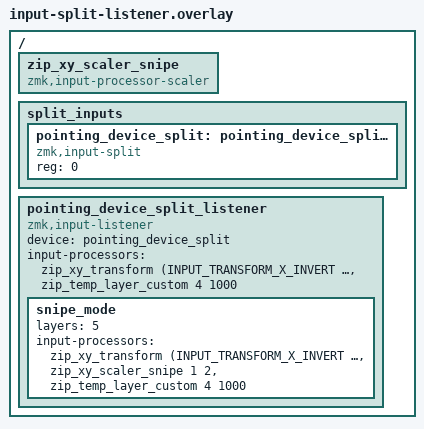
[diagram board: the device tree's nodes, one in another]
/{
    zip_xy_scaler_snipe: zip_xy_scaler_snipe {
        compatible = "zmk,input-processor-scaler";
        #input-processor-cells = <2>;
    };

    split_inputs {
        #address-cells = <1>;
        #size-cells = <0>;

        pointing_device_split: pointing_device_split@0 {
            compatible = "zmk,input-split";
            reg = <0>;
        };
    };

    pointing_device_split_listener: pointing_device_split_listener {
        compatible = "zmk,input-listener";
        device = <&pointing_device_split>;
        status = "okay";
        input-processors = <&zip_xy_transform (INPUT_TRANSFORM_X_INVERT | INPUT_TRANSFORM_Y_INVERT)>, <&zip_temp_layer_custom 4 1000>;

        snipe_mode {
            layers = <5>;
            input-processors = <&zip_xy_transform (INPUT_TRANSFORM_X_INVERT | INPUT_TRANSFORM_Y_INVERT)>, <&zip_xy_scaler_snipe 1 2>, <&zip_temp_layer_custom 4 1000>;
        };
     };
};
